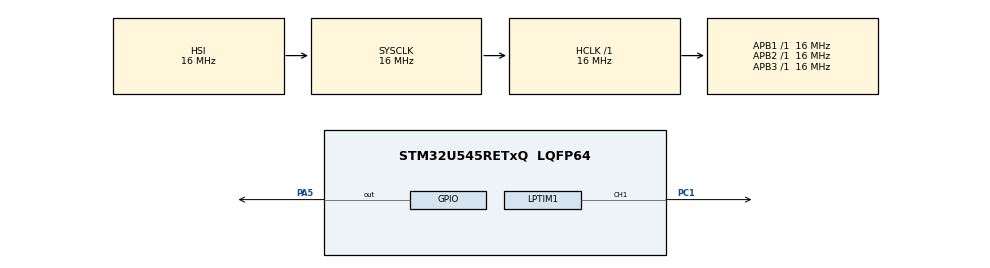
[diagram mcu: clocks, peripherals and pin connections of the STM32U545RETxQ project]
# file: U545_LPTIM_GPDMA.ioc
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CORTEX_M33_NS.userName=CORTEX_M33
GPDMA1.BLKHWREQUEST_GPDMACH0-SIMPLEREQUEST_GPDMACH0=DMA_BREQ_BLOCK
GPDMA1.CIRCULARMODE_GPDMACH0=DISABLE
GPDMA1.DESTDATAWIDTH_GPDMACH0=DMA_DEST_DATAWIDTH_WORD
GPDMA1.DESTINC_GPDMACH0=DMA_DINC_FIXED
GPDMA1.DIRECTION_GPDMACH0=DMA_MEMORY_TO_PERIPH
GPDMA1.IPHANDLE_GPDMACH0-SIMPLEREQUEST_GPDMACH0=__NULL
GPDMA1.REQUEST_GPDMACH0=GPDMA1_REQUEST_LPTIM1_IC1
GPDMA1.SRCDATAWIDTH_GPDMACH0=DMA_SRC_DATAWIDTH_WORD
GPDMA1.SRCINC_GPDMACH0=DMA_SINC_INCREMENTED
GPDMA1.TRANSFERALLOCATEDPORTDEST_GPDMACH0=DMA_DEST_ALLOCATED_PORT0
GPDMA1.TRIGGERPOLARITY_GPDMACH0=DMA_TRIG_POLARITY_MASKED
LPTIM1.ClockPrescaler=LPTIM_PRESCALER_DIV16
LPTIM1.OCPulse_1=0
LPTIM1.Period=999
Mcu.Family=STM32U5
Mcu.Name=STM32U545RETxQ
Mcu.Package=LQFP64
NVIC.GPDMA1_Channel0_IRQn=true\:0\:0\:false\:false\:true\:true\:true\:true
NVIC.LPTIM1_IRQn=true\:0\:0\:false\:false\:true\:true\:true\:true
NVIC.PriorityGroup=NVIC_PRIORITYGROUP_4
PA5.Signal=GPIO_Output
PC1.Signal=S_LPTIM1_CH1
PWR.PowerMode=PWR_SMPS_SUPPLY
ProjectManager.HeapSize=0x200
ProjectManager.StackSize=0x400
ProjectManager.TargetToolchain=STM32CubeIDE
RCC.ADCFreq_Value=16000000
RCC.AHBFreq_Value=16000000
RCC.APB1Freq_Value=16000000
RCC.APB1TimFreq_Value=16000000
RCC.APB2Freq_Value=16000000
RCC.APB2TimFreq_Value=16000000
RCC.APB3Freq_Value=16000000
RCC.CortexFreq_Value=16000000
RCC.DACCLockSelectionVirtual=RCC_DAC1CLKSOURCE_LSI
RCC.DACCLockSelectionVirtualString=RCC_DAC1CLKSOURCE_LSI
RCC.EPOD_VALUE=4000000
RCC.HCLKFreq_Value=16000000
RCC.HSE_VALUE=16000000
RCC.HSI48_VALUE=48000000
RCC.HSI_VALUE=16000000
RCC.LSE_VALUE=32768
RCC.LSIDIV_VALUE=32000
RCC.MSI_VALUE=4000000
RCC.SYSCLKFreq_VALUE=16000000
RCC.SYSCLKSource=RCC_SYSCLKSOURCE_HSI
RCC.USBFreq_Value=48000000
RCC.VCOOutputFreq_Value=516000000
SH.S_LPTIM1_CH1.0=LPTIM1_CH1,OutputIO_CH1
VP_GPDMA1_VS_GPDMACH0.Mode=SIMPLEREQUEST_GPDMACH0
VP_ICACHE_VS_ICACHE.Mode=DirectMappedCache
VP_LPBAMQUEUE_VS_QUEUE.Mode=QUEUEMODE
VP_LPTIM1_VS_CH1.Mode=Channel_1_Active
VP_LPTIM1_VS_LPTIM_counterModeInternalClock.Mode=Counts__internal_clock_event_00
VP_MEMORYMAP_VS_MEMORYMAP.Mode=CurAppReg
VP_NUCLEO-U545RE-Q_VS_BSP_COMMON.Mode=COMMON
VP_PWR_VS_LPOM.Mode=PowerOptimisation
VP_PWR_VS_SECSignals.Mode=Security/Privilege
board=NUCLEO-U545RE-Q

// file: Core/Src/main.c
/* USER CODE BEGIN Header */
/**
  ******************************************************************************
  * @file           : main.c
  * @brief          : Main program body
  ******************************************************************************
  * @attention
  *
  * Copyright (c) 2026 STMicroelectronics.
  * All rights reserved.
  *
  * This software is licensed under terms that can be found in the LICENSE file
  * in the root directory of this software component.
  * If no LICENSE file comes with this software, it is provided AS-IS.
  *
  ******************************************************************************
  */
/* USER CODE END Header */
#include "main.h"

LPTIM_HandleTypeDef hlptim1;
DMA_HandleTypeDef handle_GPDMA1_Channel0;

/* USER CODE BEGIN PV */
#define CCRValue_BufferSize     37

ALIGN_32BYTES (uint32_t DiscontinuousSineCCRValue_Buffer[CCRValue_BufferSize]) =
{
  14999, 17603, 20128, 22498, 24640, 26488, 27988, 29093, 29770,
  29998, 29770, 29093, 27988, 26488, 24640, 22498, 20128, 17603,
  14999, 12394, 9869, 7499, 5357, 3509, 2009, 904, 227, 1, 227,
  904, 2009, 3509, 5357, 7499, 9869, 12394, 14999
};

/* USER CODE END PV */

void SystemClock_Config(void);
static void SystemPower_Config(void);
static void MX_GPIO_Init(void);
static void MX_GPDMA1_Init(void);
static void MX_ICACHE_Init(void);
static void MX_LPTIM1_Init(void);

int main(void)
{

  /* MCU Configuration--------------------------------------------------------*/

  /* Reset of all peripherals, Initializes the Flash interface and the Systick. */
  HAL_Init();

  /* Configure the System Power */
  SystemPower_Config();

  /* Configure the system clock */
  SystemClock_Config();

  /* Initialize all configured peripherals */
  MX_GPIO_Init();
  MX_GPDMA1_Init();
  MX_ICACHE_Init();
  MX_LPTIM1_Init();
  /* USER CODE BEGIN 2 */

    /* Start interrupt on compare match (for PA5 toggle) */

      /* Start PWM output on CH1 (PC1) */
//      if (HAL_LPTIM_PWM_Start(&hlptim1,LPTIM_CHANNEL_1) != HAL_OK)
//      {
//        Error_Handler();
//      }

      HAL_LPTIM_PWM_Start_DMA(&hlptim1, LPTIM_CHANNEL_1, DiscontinuousSineCCRValue_Buffer, CCRValue_BufferSize);

  /* USER CODE END 2 */

  /* Infinite loop */
  /* USER CODE BEGIN WHILE */
  while (1)
  {
    /* CPU can sleep; PA5 is toggled in DMA callback */
  }
    /* USER CODE END WHILE */

}

void SystemClock_Config(void)
{
  RCC_OscInitTypeDef RCC_OscInitStruct = {0};
  RCC_ClkInitTypeDef RCC_ClkInitStruct = {0};

  /** Configure the main internal regulator output voltage
  */
  if (HAL_PWREx_ControlVoltageScaling(PWR_REGULATOR_VOLTAGE_SCALE4) != HAL_OK)
  {
    Error_Handler();
  }

  /** Initializes the CPU, AHB and APB buses clocks
  */
  RCC_OscInitStruct.OscillatorType = RCC_OSCILLATORTYPE_HSI|RCC_OSCILLATORTYPE_MSIK;
  RCC_OscInitStruct.HSIState = RCC_HSI_ON;
  RCC_OscInitStruct.HSICalibrationValue = RCC_HSICALIBRATION_DEFAULT;
  RCC_OscInitStruct.MSICalibrationValue = RCC_MSICALIBRATION_DEFAULT;
  RCC_OscInitStruct.MSIKClockRange = RCC_MSIKRANGE_4;
  RCC_OscInitStruct.MSIKState = RCC_MSIK_ON;
  RCC_OscInitStruct.PLL.PLLState = RCC_PLL_NONE;
  if (HAL_RCC_OscConfig(&RCC_OscInitStruct) != HAL_OK)
  {
    Error_Handler();
  }

  /** Initializes the CPU, AHB and APB buses clocks
  */
  RCC_ClkInitStruct.ClockType = RCC_CLOCKTYPE_HCLK|RCC_CLOCKTYPE_SYSCLK
                              |RCC_CLOCKTYPE_PCLK1|RCC_CLOCKTYPE_PCLK2
                              |RCC_CLOCKTYPE_PCLK3;
  RCC_ClkInitStruct.SYSCLKSource = RCC_SYSCLKSOURCE_HSI;
  RCC_ClkInitStruct.AHBCLKDivider = RCC_SYSCLK_DIV1;
  RCC_ClkInitStruct.APB1CLKDivider = RCC_HCLK_DIV1;
  RCC_ClkInitStruct.APB2CLKDivider = RCC_HCLK_DIV1;
  RCC_ClkInitStruct.APB3CLKDivider = RCC_HCLK_DIV1;

  if (HAL_RCC_ClockConfig(&RCC_ClkInitStruct, FLASH_LATENCY_1) != HAL_OK)
  {
    Error_Handler();
  }

  /** Enable the force of MSIK in stop mode
  */
  __HAL_RCC_MSIKSTOP_ENABLE();
}

/**
  * @brief Power Configuration
  * @retval None
  */
static void SystemPower_Config(void)
{

  /*
   * Switch to SMPS regulator instead of LDO
   */
  if (HAL_PWREx_ConfigSupply(PWR_SMPS_SUPPLY) != HAL_OK)
  {
    Error_Handler();
  }
}

static void MX_GPDMA1_Init(void)
{

  /* Peripheral clock enable */
  __HAL_RCC_GPDMA1_CLK_ENABLE();

  /* GPDMA1 interrupt Init */
    HAL_NVIC_SetPriority(GPDMA1_Channel0_IRQn, 0, 0);
    HAL_NVIC_EnableIRQ(GPDMA1_Channel0_IRQn);

}

static void MX_ICACHE_Init(void)
{

  /** Enable instruction cache in 1-way (direct mapped cache)
  */
  if (HAL_ICACHE_ConfigAssociativityMode(ICACHE_1WAY) != HAL_OK)
  {
    Error_Handler();
  }
  if (HAL_ICACHE_Enable() != HAL_OK)
  {
    Error_Handler();
  }

}

static void MX_LPTIM1_Init(void)
{

  LPTIM_OC_ConfigTypeDef sConfig1 = {0};

  hlptim1.Instance = LPTIM1;
  hlptim1.Init.Clock.Source = LPTIM_CLOCKSOURCE_APBCLOCK_LPOSC;
  hlptim1.Init.Clock.Prescaler = LPTIM_PRESCALER_DIV16;
  hlptim1.Init.Trigger.Source = LPTIM_TRIGSOURCE_SOFTWARE;
  hlptim1.Init.Period = 29998;
  hlptim1.Init.UpdateMode = LPTIM_UPDATE_IMMEDIATE;
  hlptim1.Init.CounterSource = LPTIM_COUNTERSOURCE_INTERNAL;
  hlptim1.Init.Input1Source = LPTIM_INPUT1SOURCE_GPIO;
  hlptim1.Init.Input2Source = LPTIM_INPUT2SOURCE_GPIO;
  hlptim1.Init.RepetitionCounter = 0;
  if (HAL_LPTIM_Init(&hlptim1) != HAL_OK)
  {
    Error_Handler();
  }
  sConfig1.Pulse =  DiscontinuousSineCCRValue_Buffer[0];
  sConfig1.OCPolarity = LPTIM_OCPOLARITY_HIGH;
  if (HAL_LPTIM_OC_ConfigChannel(&hlptim1, &sConfig1, LPTIM_CHANNEL_1) != HAL_OK)
  {
    Error_Handler();
  }
  HAL_LPTIM_MspPostInit(&hlptim1);

}

static void MX_GPIO_Init(void)
{
  GPIO_InitTypeDef GPIO_InitStruct = {0};

  /* GPIO Ports Clock Enable */
  __HAL_RCC_GPIOC_CLK_ENABLE();
  __HAL_RCC_GPIOA_CLK_ENABLE();

  /*Configure GPIO pin Output Level */
  HAL_GPIO_WritePin(GPIOA, GPIO_PIN_5, GPIO_PIN_RESET);

  /*Configure GPIO pin : PA5 */
  GPIO_InitStruct.Pin = GPIO_PIN_5;
  GPIO_InitStruct.Mode = GPIO_MODE_OUTPUT_PP;
  GPIO_InitStruct.Pull = GPIO_NOPULL;
  GPIO_InitStruct.Speed = GPIO_SPEED_FREQ_LOW;
  HAL_GPIO_Init(GPIOA, &GPIO_InitStruct);

}

/* USER CODE BEGIN 4 */
void HAL_LPTIM_CompareMatchCallback(LPTIM_HandleTypeDef *hlptim)
{
  if (hlptim->Instance == LPTIM1)
  {
    HAL_GPIO_TogglePin(GPIOA, GPIO_PIN_5);
  }
}
/* USER CODE END 4 */

void Error_Handler(void)
{
  __disable_irq();
  while (1)
  {
  }
}
